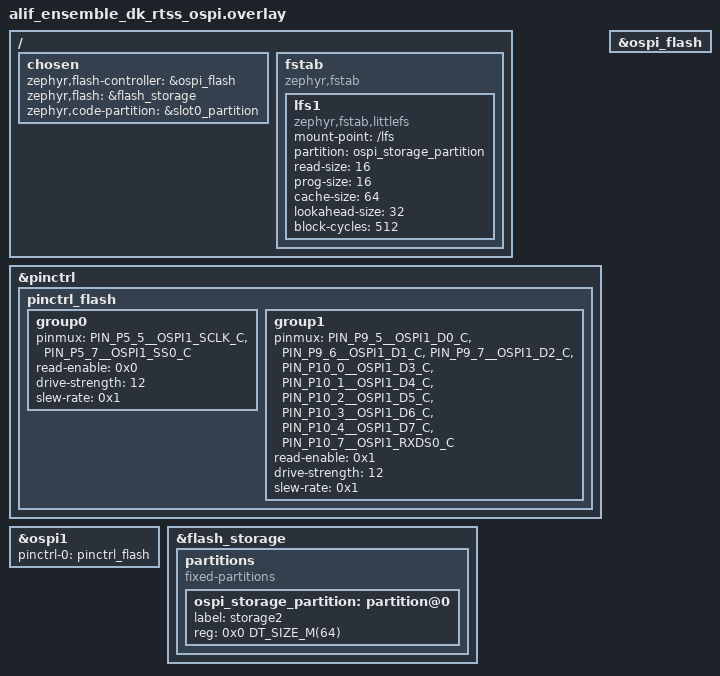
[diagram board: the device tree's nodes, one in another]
/*
 * Copyright (c) 2025 Alif Semiconductor.
 * SPDX-License-Identifier: Apache-2.0
 */

&pinctrl {
	pinctrl_flash:pinctrl_flash {
		group0 {
			pinmux = <PIN_P5_5__OSPI1_SCLK_C>,
				 <PIN_P5_7__OSPI1_SS0_C>;
			read-enable = <0x0>;
			drive-strength = <12>;
			slew-rate = <0x1>;
		};
		group1 {
			pinmux = <PIN_P9_5__OSPI1_D0_C>,
				 <PIN_P9_6__OSPI1_D1_C>,
				 <PIN_P9_7__OSPI1_D2_C>,
				 <PIN_P10_0__OSPI1_D3_C>,
				 <PIN_P10_1__OSPI1_D4_C>,
				 <PIN_P10_2__OSPI1_D5_C>,
				 <PIN_P10_3__OSPI1_D6_C>,
				 <PIN_P10_4__OSPI1_D7_C>,
				 <PIN_P10_7__OSPI1_RXDS0_C>;
			read-enable = <0x1>;
			drive-strength = <12>;
			slew-rate = <0x1>;
		};
	};
};

&ospi1 {
	pinctrl-0 = <&pinctrl_flash>;
	status = "okay";
};

&ospi_flash {
	status = "okay";
};

&ospi1 {
	status = "okay";
	pinctrl-0 = <&pinctrl_flash>;
};

/{
	chosen {
		zephyr,flash-controller = &ospi_flash;
		zephyr,flash = &flash_storage;
		zephyr,code-partition = &slot0_partition;
	};

	fstab {
		compatible = "zephyr,fstab";

		lfs1: lfs1 {
			compatible = "zephyr,fstab,littlefs";
			mount-point = "/lfs";
			partition = <&ospi_storage_partition>;
			read-size = <16>;
			prog-size = <16>;
			cache-size = <64>;
			lookahead-size = <32>;
			block-cycles = <512>;
		};
	};
};

/delete-node/ &storage_partition;

/* OSPI Flash storage*/
&flash_storage {
	partitions {
		#address-cells = <1>;
		#size-cells = <1>;
		compatible = "fixed-partitions";

		/* Set 64MB of OSPI flash as second littlefs partition */
		ospi_storage_partition: partition@0 {
			label = "storage2";
			reg = <0x0 DT_SIZE_M(64)>;
		};
	};
};
